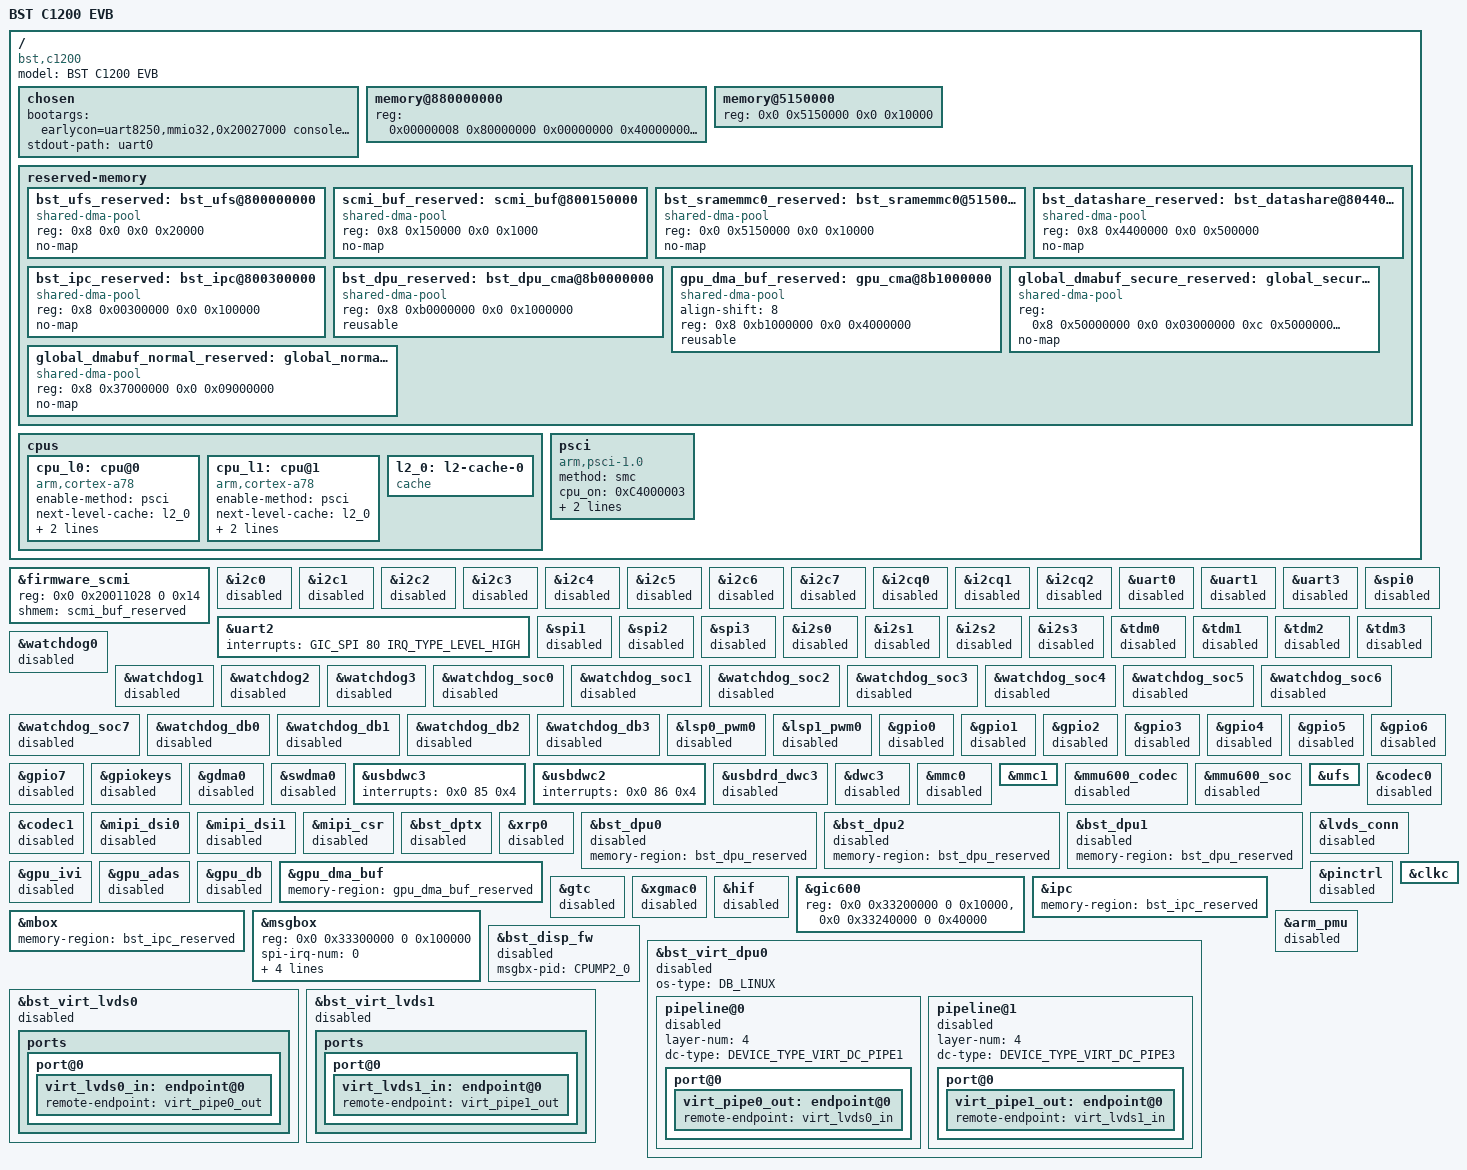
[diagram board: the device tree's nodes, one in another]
// SPDX-License-Identifier: GPL-2.0+
/dts-v1/;
#include "bstc1200.dtsi"

/ {
	compatible = "bst,c1200";
	model = "BST C1200 EVB";

	chosen {
		bootargs = "earlycon=uart8250,mmio32,0x20027000 console=ttyS0,115200n8 rdinit=/sbin/init root=/dev/ram rw init=/linuxrc rodata=n";
		stdout-path = "uart0";
	};

// OS 1GB
	memory@880000000 {
		device_type = "memory";
		reg = <0x00000008 0x80000000 0x00000000 0x40000000
			   0x00000008 0x37000000 0x00000000 0x09000000
			   0x8 0x50000000 0x0 0x03000000
			   0xc 0x50000000 0x0 0x03000000
		>;
	};

//emmc
	memory@5150000 {
		device_type = "memory";
		reg = <0x0 0x5150000 0x0 0x10000>;
	};

	reserved-memory {
		#address-cells = <2>;
		#size-cells = <2>;
		ranges;

		bst_ufs_reserved: bst_ufs@800000000 {
			compatible = "shared-dma-pool";
			reg = <0x8 0x0 0x0 0x20000>;
			no-map;
		};

			scmi_buf_reserved: scmi_buf@800150000 {
			compatible = "shared-dma-pool";
			reg = <0x8 0x150000 0x0 0x1000>;
			no-map;
		};

		bst_sramemmc0_reserved: bst_sramemmc0@5150000{
			compatible = "shared-dma-pool";
			reg = <0x0 0x5150000 0x0 0x10000>;
			no-map;
		};

		bst_datashare_reserved: bst_datashare@804400000 {
			compatible = "shared-dma-pool";
			reg = <0x8 0x4400000 0x0 0x500000>;
			no-map;
		};


		bst_ipc_reserved: bst_ipc@800300000 {
			compatible = "shared-dma-pool";
			reg = <0x8 0x00300000 0x0 0x100000>;
			no-map;
		};


		bst_dpu_reserved: bst_dpu_cma@8b0000000 {
			compatible = "shared-dma-pool";
			reg = <0x8 0xb0000000 0x0 0x1000000>;
			reusable;
		};

		/* gpu memory pool */
		gpu_dma_buf_reserved: gpu_cma@8b1000000 {
			compatible = "shared-dma-pool";
			align-shift = <8>;
			reg = <0x8 0xb1000000 0x0 0x4000000>;
			reusable;
		};
		/*reserved for global secure dmabuf */
		global_dmabuf_secure_reserved: global_secure_dmabuf@850000000 {
			compatible = "shared-dma-pool";
			reg = <0x8 0x50000000 0x0 0x03000000
                   0xc 0x50000000 0x0 0x03000000
			>;
			no-map;
		};
		/*reserved for global normal dmabuf */
		global_dmabuf_normal_reserved: global_normal_dmabuf@837000000 {
			compatible = "shared-dma-pool";
			reg = <0x8 0x37000000 0x0 0x09000000>;
			no-map;
		};
	};
//

	cpus {
		#address-cells = <1>;
		#size-cells = <0>;

		cpu_l0: cpu@0 {
			compatible = "arm,cortex-a78", "arm,armv8";
			device_type = "cpu";
			enable-method = "psci";
			next-level-cache = <&l2_0>;
			reg = <0x0>;
			freq-domain = <&cpufreq 2>;
		};
		cpu_l1: cpu@1 {
			compatible = "arm,cortex-a78", "arm,armv8";
			device_type = "cpu";
			enable-method = "psci";
			next-level-cache = <&l2_0>;
			reg = <0x100>;
			freq-domain = <&cpufreq 2>;
		};

		l2_0: l2-cache-0 {
			compatible = "cache";
		};
	};


	psci {
		compatible	= "arm,psci-1.0";
		method		= "smc";
		cpu_on		= <0xC4000003>;
		cpu_off		= <0x84000002>;
		cpu_suspend	= <0xC4000001>;
	};

};



&firmware_scmi {
	status = "okay";
	reg = <0x0 0x20011028 0 0x14>;
	shmem = <&scmi_buf_reserved>;
};





&i2c0 {
	status = "disable";
};
&i2c1 {
	status = "disable";
};
&i2c2 {
	status = "disable";
};
&i2c3 {
	status = "disable";
};
&i2c4 {
	status = "disable";
};
&i2c5 {
	status = "disable";
};
&i2c6 {
	status = "disable";
};
&i2c7 {
	status = "disable";
};
&i2cq0 {
	status = "disable";
};
&i2cq1 {
	status = "disable";
};
&i2cq2 {
	status = "disable";
};

&uart0 {
	status = "disable";
};
&uart1 {
	status = "disable";
};
&uart2 {
	status = "okay";
	interrupts = <GIC_SPI 80 IRQ_TYPE_LEVEL_HIGH>;
};
&uart3 {
	status = "disable";
};

&spi0 {
	status = "disable";
};
&spi1 {
	status = "disable";
};
&spi2 {
	status = "disable";
};
&spi3 {
	status = "disable";
};

&i2s0 {
	status = "disable";
};
&i2s1 {
	status = "disable";
};
&i2s2 {
	status = "disable";
};
&i2s3 {
	status = "disable";
};

&tdm0 {
	status = "disable";
};
&tdm1 {
	status = "disable";
};
&tdm2 {
	status = "disable";
};
&tdm3 {
	status = "disable";
};

&watchdog0 {
	status = "disable";
};
&watchdog1 {
	status = "disable";
};
&watchdog2 {
	status = "disable";
};
&watchdog3 {
	status = "disable";
};
&watchdog_soc0 {
	status = "disable";
};
&watchdog_soc1 {
	status = "disable";
};
&watchdog_soc2 {
	status = "disable";
};
&watchdog_soc3 {
	status = "disable";
};

&watchdog_soc4 {
	status = "disable";
};
&watchdog_soc5 {
	status = "disable";
};
&watchdog_soc6 {
	status = "disable";
};
&watchdog_soc7 {
	status = "disable";
};
&watchdog_db0 {
	status = "disable";
};
&watchdog_db1 {
	status = "disable";
};
&watchdog_db2 {
	status = "disable";
};
&watchdog_db3 {
	status = "disable";
};

&lsp0_pwm0 {
	status = "disable";
};
&lsp1_pwm0 {
	status = "disable";
};

&gpio0 {
	status = "disable";
};
&gpio1 {
	status = "disable";
};
&gpio2 {
	status = "disable";
};
&gpio3 {
	status = "disable";
};
&gpio4 {
	status = "disable";
};
&gpio5 {
	status = "disable";
};
&gpio6 {
	status = "disable";
};
&gpio7 {
	status = "disable";
};
&gpiokeys {
	status = "disable";
};

&gdma0 {
	status = "disable";
};

&swdma0 {
	status = "disable";
};

&usbdwc3 {
	interrupts = <0x0 85 0x4>;
};
&usbdwc2 {
	interrupts = <0x0 86 0x4>;
};
&usbdrd_dwc3 {
	status = "disable";
};
&dwc3 {
	status = "disable";
};

&mmc0 {
	status = "disable";
};
&mmc1 {
	status = "okay";
};

&mmu600_codec {
	status = "disable";
};
&mmu600_soc {
	status = "disable";
};

&ufs {
	status = "okay";
};

&codec0 {
	status = "disable";
};
&codec1 {
	status = "disable";
};

&mipi_dsi0 {
	status = "disable";
};
&mipi_dsi1 {
	status = "disable";
};
&mipi_csr {
	status = "disable";
};

&bst_dptx {
	status = "disable";
};

&xrp0 {
	status = "disable";
};

&bst_dpu0 {
	status = "disable";
	memory-region = <&bst_dpu_reserved>;
};
&bst_dpu2 {
	status = "disable";
	memory-region = <&bst_dpu_reserved>;
};
&bst_dpu1 {
	status = "disable";
	memory-region = <&bst_dpu_reserved>;
};

&lvds_conn {
	status = "disable";
};

&gpu_ivi {
	status = "disable";
};

&gpu_adas {
	status = "disable";
};

&gpu_db {
	status = "disable";
};

&gpu_dma_buf {
	memory-region = <&gpu_dma_buf_reserved>;
};

&pinctrl {
	status = "disable";
};

&clkc {
	status = "okay";
};

&gtc {
	status = "disable";
};

&xgmac0 {
	status = "disable";
};

&hif {
	status = "disable";
};

&gic600 {
	status = "okay";
	reg = <0x0 0x33200000 0 0x10000>,	// GICD
			<0x0 0x33240000 0 0x40000>;	// GICR
};


&ipc {
	status = "okay";
	memory-region = <&bst_ipc_reserved>;
};

&mbox {
	status = "okay";
	memory-region = <&bst_ipc_reserved>;
};


&msgbox {
	status = "okay";
	reg =   <0x0 0x33300000 0 0x100000>; //db
	spi-irq-num = <0>;
	filter-num = <2>;
interrupt-parent = <&gic600>;
	interrupts =    <
	GIC_PPI 4 (GIC_CPU_MASK_SIMPLE(8) | IRQ_TYPE_LEVEL_LOW)
	GIC_PPI 15 (GIC_CPU_MASK_SIMPLE(8) | IRQ_TYPE_LEVEL_LOW)
	>;
	#mbox-cells = <0x1>;
};

&arm_pmu {
	status = "disable";
};

&bst_disp_fw {
	status = "disable";
	msgbx-pid = "CPUMP2_0"; /* "CPUMP2_0" "CPUMP2_1" */
};

&bst_virt_dpu0 {
	status = "disable";
	os-type = "DB_LINUX"; /* "ADAS_LINUX", "DB_LINUX" */
	pipeline@0 {
		status = "disable";
		layer-num = <4>;
		dc-type = "DEVICE_TYPE_VIRT_DC_PIPE1";
		port@0 {
			virt_pipe0_out: endpoint@0 {
				remote-endpoint = <&virt_lvds0_in>;
			};
		};
	};
	pipeline@1 {
		status = "disable";
		layer-num = <4>;
		dc-type = "DEVICE_TYPE_VIRT_DC_PIPE3";
		port@0 {
			virt_pipe1_out: endpoint@0 {
				remote-endpoint = <&virt_lvds1_in>;
			};
		};
	};
};

&bst_virt_lvds0 {
	status = "disable";
	ports {
		port@0 {
			virt_lvds0_in: endpoint@0 {
				remote-endpoint = <&virt_pipe0_out>;
			};
		};
	};
};

&bst_virt_lvds1 {
	status = "disable";
	ports {
		port@0 {
			virt_lvds1_in: endpoint@0 {
				remote-endpoint = <&virt_pipe1_out>;
			};
		};
	};
};
